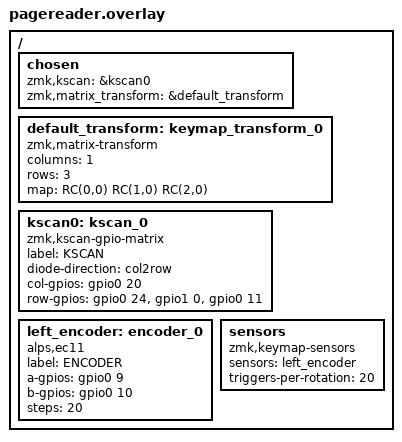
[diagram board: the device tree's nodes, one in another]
#include <dt-bindings/zmk/matrix_transform.h>

/ {
    chosen {
        zmk,kscan = &kscan0;
        zmk,matrix_transform = &default_transform;
    };

    default_transform: keymap_transform_0 {
        compatible = "zmk,matrix-transform";
        columns = <1>;
        rows = <3>;
        map = <
            RC(0,0)
            RC(1,0)
            RC(2,0)
        >;
    };

    kscan0: kscan_0 {
        compatible = "zmk,kscan-gpio-matrix";
        label = "KSCAN";
        diode-direction = "col2row";

        col-gpios
            = <&gpio0 20 GPIO_ACTIVE_HIGH>
            ;

        row-gpios
            = <&gpio0 24 (GPIO_ACTIVE_HIGH | GPIO_PULL_DOWN)>
            , <&gpio1  0 (GPIO_ACTIVE_HIGH | GPIO_PULL_DOWN)>
            , <&gpio0 11 (GPIO_ACTIVE_HIGH | GPIO_PULL_DOWN)>
            ;
    };

    left_encoder: encoder_0 {
        compatible = "alps,ec11";
        label = "ENCODER";
        a-gpios = <&gpio0  9 (GPIO_ACTIVE_HIGH | GPIO_PULL_UP)>;
        b-gpios = <&gpio0 10 (GPIO_ACTIVE_HIGH | GPIO_PULL_UP)>;
        steps = <20>;
        status = "okay";
    };

    sensors {
        compatible = "zmk,keymap-sensors";
        sensors = <&left_encoder>;
        triggers-per-rotation = <20>;
    };
};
